AUTOSAR XML (schema 00046)
package /Runnables
  sender receiver interface SR_IF_Inputs
    data VAL1: type=uint16
    data VAL2: type=uint16
  sender receiver interface SR_IF_Outputs
    data Result: type=uint32
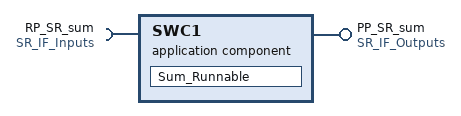
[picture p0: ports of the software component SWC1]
  application sw component type SWC1
    provide port PP_SR_sum: provided-interface=SR_IF_Outputs
    require port RP_SR_sum: required-interface=SR_IF_Inputs
    behavior SWC1_Behavior
      runnable Sum_Runnable: symbol=Set_CMD
        data-read-access:
          access Data_val1: accessed-variable=RP_SR_sum.VAL1
          access Data_val2: accessed-variable=RP_SR_sum.VAL2
        data-write-access:
          access Data_SumResult: accessed-variable=PP_SR_sum.Result
